# LPC5516 register map
Vendor: nxp.com; File version: 1.0
CPU: CM33 r2p0, little endian, MPU, FPU, VTOR, 3 interrupt priority bits
Registers are 32-bit, read-write, reset 0x0 unless marked. A register's access mark holds for its fields unless they carry their own. Offsets are from the block's base; [hi:lo] are bit positions; {n}, {i} and the like mark numbered series.

## CDOG
Base 0x400A1000
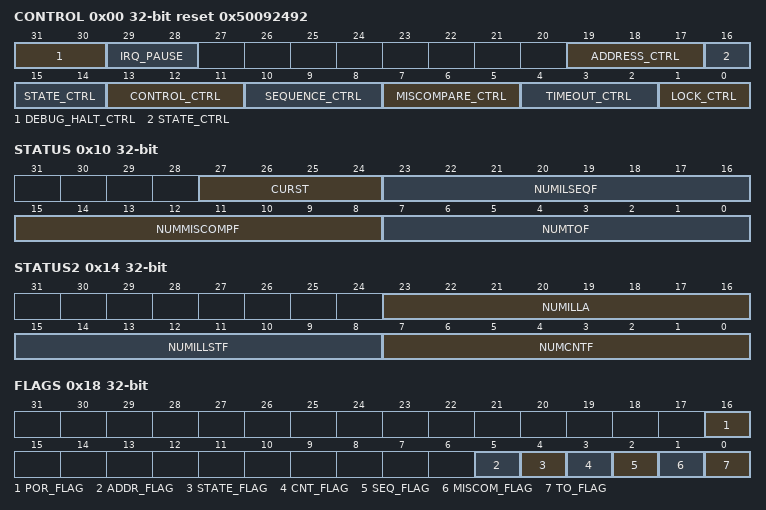
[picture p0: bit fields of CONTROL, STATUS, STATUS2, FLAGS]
0x00 CONTROL reset 0x50092492 — The control fields, which constitute CONTROL, control all controllable attributes of the module, including those of CONTROL itself.
  [31:30] DEBUG_HALT_CTRL — DEBUG_HALT control field
  [29:28] IRQ_PAUSE — IRQ pause control field
  [19:17] ADDRESS_CTRL — ADDRESS control field
  [16:14] STATE_CTRL — STATE control field
  [13:11] CONTROL_CTRL — CONTROL control field
  [10:8] SEQUENCE_CTRL — SEQUENCE control field
  [7:5] MISCOMPARE_CTRL — MISCOMPARE control field
  [4:2] TIMEOUT_CTRL — TIMEOUT control
  [1:0] LOCK_CTRL — Lock control field
0x04 RELOAD reset 0xFFFFFFFF — Instruction timer reload
  [31:0] RLOAD — Inst. Timer reload value
0x08 INSTRUCTION_TIMER reset 0xFFFFFFFF — The INSTRUCTION TIMER itself
  [31:0] INSTIM — INSTRUCTION TIMER 32-bit value
0x0C SECURE_COUNTER — Also known as SEC_CNT
  [31:0] SECCNT — Secure Counter
0x10 STATUS ro — Status register (1 of 2)
  [27:24] CURST — Current State
  [23:16] NUMILSEQF — Number of illegal sequence faults
  [15:8] NUMMISCOMPF — Number of Miscompare Faults
  [7:0] NUMTOF — Number of Timeout Faults
0x14 STATUS2 ro — STATUS register (2 of 2)
  [23:16] NUMILLA — Number of (illegal) address faults
  [15:8] NUMILLSTF — Number (of) state faults
  [7:0] NUMCNTF — Number (of) control faults
0x18 FLAGS — Hardware flags
  [16] POR_FLAG — Power-on reset flag
  [5] ADDR_FLAG — Address flag
  [4] STATE_FLAG
  [3] CNT_FLAG — Control (fault) flag
  [2] SEQ_FLAG — Sequence flag
  [1] MISCOM_FLAG — Miscompare flag
  [0] TO_FLAG — Timeout flag
0x1C PERSISTENT — Persistent (Ad. Hoc., quasi-NV) data storage
  [31:0] PERSIS — 32 regs free for user SW to enjoy
0x20 START wo — Write address for issuing the START command.
  [31:0] STRT — Address of start command access
0x24 STOP wo — Write address for issuing the STOP command.
  [31:0] STP — Address of stop command access
0x28 RESTART wo — Write address for issuing the RESTART command.
  [31:0] RSTRT
0x2C ADD wo — Write address for issuing the ADD command.
  [31:0] AD — Address of ADD command
0x30 ADD1 wo — Write address for issuing the ADD1 command.
  [31:0] AD1 — Address of ADD1 command.
0x34 ADD16 wo — Write address for issuing the ADD16 command.
  [31:0] AD16 — Address of ADD16
0x38 ADD256 wo — Write address for issuing the ADD16 command.
  [31:0] AD256 — Address of ADD256 command
0x3C SUB wo — Write address for issuing the SUB command.
  [31:0] S0B — Address of SUB command.
0x40 SUB1 wo — Write address for issuing the SUB1 command.
  [31:0] S1B — Address of SUB1 command.
0x44 SUB16 wo — Write address for issuing the SUB16 command.
  [31:0] SB16 — Address of SUB16 command.
0x48 SUB256 wo — Write address for issuing the SUB256 command.
  [31:0] SB256 — Address of (you guessed it) SUB256 command.

## SCnSCB
Base 0xE000E000
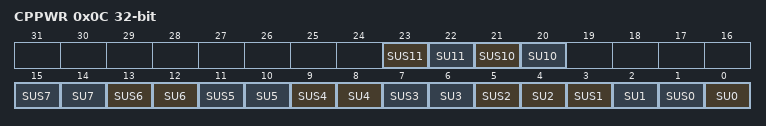
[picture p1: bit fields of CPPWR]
0x0C CPPWR reset not defined — Coprocessor Power Control Register
  [23] SUS11 — State UNKNOWN Secure only 11.
  [22] SU11 — State UNKNOWN 11.
  [21] SUS10 — State UNKNOWN Secure only 10.
    0=SECURE_AND_NON_SECURE (The SU10 field is accessible from both Security states.); 1=SECURE_ONLY (The SU10 field is only accessible from the Secure state.)
  [20] SU10 — State UNKNOWN 10.
    0=UNKNOWN_NOT_PERMITTED (The floating-point state is not permitted to become UNKNOWN.); 1=UNKNOWN_PERMITTED (The floating-point state is permitted to become UNKNOWN)
  [2n+1] SUS{n} (n=2..7) — State UNKNOWN Secure only {n}.
    0=SECURE_AND_NON_SECURE (The SU{n} field is accessible from both Security states.); 1=SECURE_ONLY (The SU{n} field is only accessible from the Secure state.)
  [2n] SU{n} (n=0..7) — State UNKNOWN {n}.
    0=UNKNOWN_NOT_PERMITTED (The coprocessor state is not permitted to become UNKNOWN.); 1=UNKNOWN_PERMITTED (The coprocessor state is permitted to become UNKNOWN.)
  [3] SUS1 — State UNKNOWN Secure only 1.
    0=SECURE_AND_NON_SECURE (The SU7 field is accessible from both Security states.); 1=SECURE_ONLY (The SU7 field is only accessible from the Secure state.)
  [1] SUS0 — State UNKNOWN Secure only 0.
    0=SECURE_AND_NON_SECURE (The SU0 field is accessible from both Security states.); 1=SECURE_ONLY (The SU0 field is only accessible from the Secure state.)
